# STM32L485JEY6 register map
File version: 1.0
Registers are 32-bit, access not given, reset 0x0 unless marked. A register's access mark holds for its fields unless they carry their own. Offsets are from the block's base; [hi:lo] are bit positions; {n}, {i} and the like mark numbered series.

## DAC
Base 0x40007400
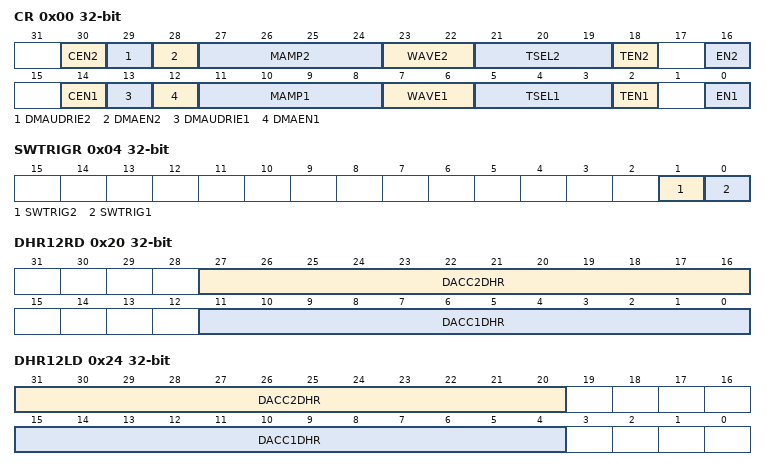
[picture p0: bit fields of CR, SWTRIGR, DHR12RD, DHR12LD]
0x00 CR
  [30] CEN2, [29] DMAUDRIE2, [28] DMAEN2, [27:24] MAMP2, [23:22] WAVE2, [21:19] TSEL2, [18] TEN2, [16] EN2, [14] CEN1, [13] DMAUDRIE1, [12] DMAEN1, [11:8] MAMP1, [7:6] WAVE1, [5:3] TSEL1, [2] TEN1, [0] EN1
0x04 SWTRIGR
  [1] SWTRIG2, [0] SWTRIG1
0x08 DHR12R1
  [11:0] DACC1DHR
0x0C DHR12L1
  [15:4] DACC1DHR
0x10 DHR8R1
  [7:0] DACC1DHR
0x14 DHR12R2
  [11:0] DACC2DHR
0x18 DHR12L2
  [15:4] DACC2DHR
0x1C DHR8R2
  [7:0] DACC2DHR
0x20 DHR12RD
  [27:16] DACC2DHR, [11:0] DACC1DHR
0x24 DHR12LD
  [31:20] DACC2DHR, [15:4] DACC1DHR
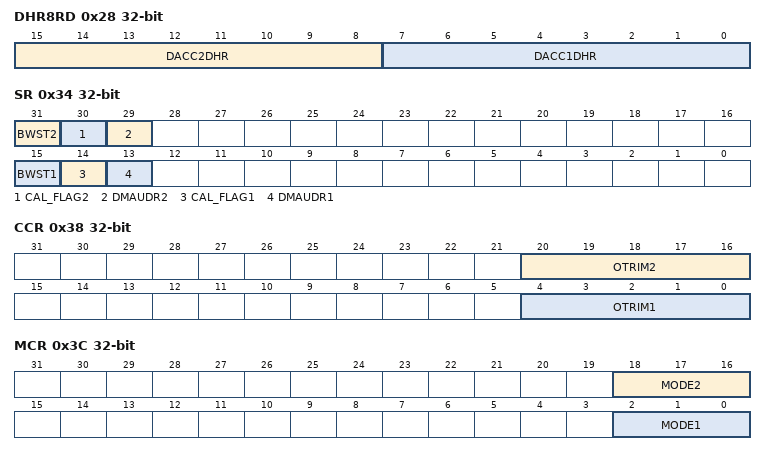
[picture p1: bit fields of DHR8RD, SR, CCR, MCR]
0x28 DHR8RD
  [15:8] DACC2DHR, [7:0] DACC1DHR
0x2C DOR1
  [11:0] DACC1DOR
0x30 DOR2
  [11:0] DACC2DOR
0x34 SR
  [31] BWST2, [30] CAL_FLAG2, [29] DMAUDR2, [15] BWST1, [14] CAL_FLAG1, [13] DMAUDR1
0x38 CCR
  [20:16] OTRIM2, [4:0] OTRIM1
0x3C MCR
  [18:16] MODE2, [2:0] MODE1
0x40 SHSR1
  [9:0] TSAMPLE1
0x44 SHSR2
  [9:0] TSAMPLE2
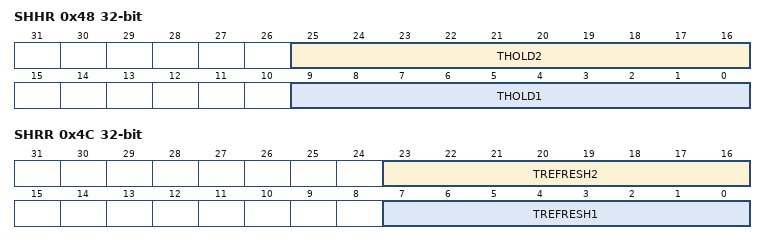
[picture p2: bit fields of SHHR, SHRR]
0x48 SHHR
  [25:16] THOLD2, [9:0] THOLD1
0x4C SHRR
  [23:16] TREFRESH2, [7:0] TREFRESH1

## DAC1
Base 0x40007400
Registers as DAC; these are added or differ:
0x08 DHR12R1
  [11:0] DACC1DHR
0x0C DHR12L1
  [15:4] DACC1DHR
0x10 DHR8R1
  [7:0] DACC1DHR
0x14 DHR12R2
  [11:0] DACC2DHR
0x18 DHR12L2
  [15:4] DACC2DHR
0x1C DHR8R2
  [7:0] DACC2DHR
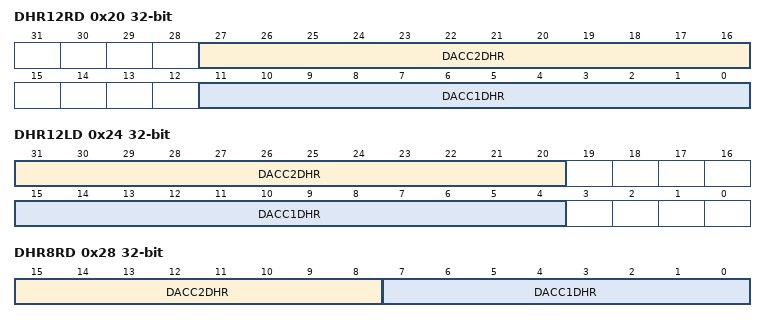
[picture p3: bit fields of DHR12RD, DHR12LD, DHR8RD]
0x20 DHR12RD
  [27:16] DACC2DHR, [11:0] DACC1DHR
0x24 DHR12LD
  [31:20] DACC2DHR, [15:4] DACC1DHR
0x28 DHR8RD
  [15:8] DACC2DHR, [7:0] DACC1DHR
0x2C DOR1
  [11:0] DACC1DOR
0x30 DOR2
  [11:0] DACC2DOR

## OPAMP
Base 0x40007800
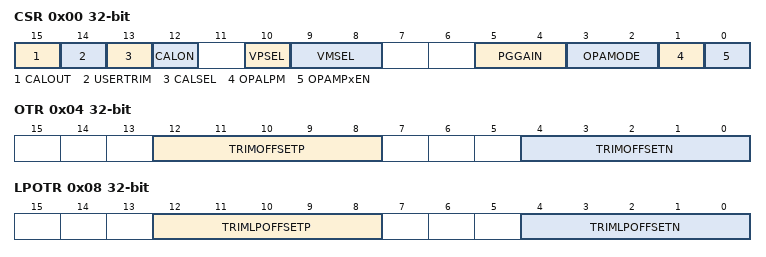
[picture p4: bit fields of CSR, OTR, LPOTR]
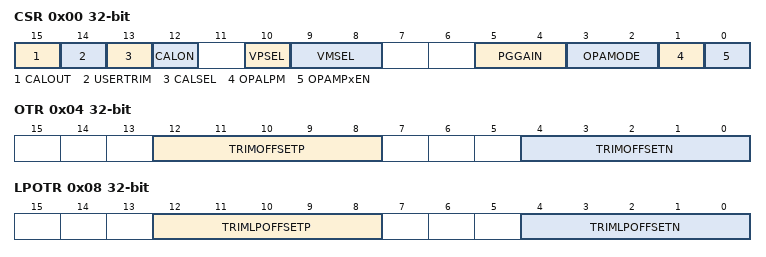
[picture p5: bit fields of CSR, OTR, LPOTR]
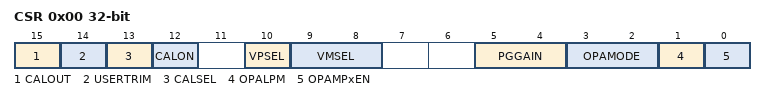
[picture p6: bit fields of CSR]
0x00 CSR
  [15] CALOUT, [14] USERTRIM, [13] CALSEL, [12] CALON, [10] VPSEL, [9:8] VMSEL, [5:4] PGGAIN, [3:2] OPAMODE, [1] OPALPM, [0] OPAMPxEN
0x04 OTR
  [12:8] TRIMOFFSETP, [4:0] TRIMOFFSETN
0x08 LPOTR
  [12:8] TRIMLPOFFSETP, [4:0] TRIMLPOFFSETN

## OPAMP1
Base 0x40007800
Same registers: OPAMP2 0x40007810
0x00 CSR
  [15] CALOUT, [14] USERTRIM, [13] CALSEL, [12] CALON, [10] VPSEL, [9:8] VMSEL, [5:4] PGGAIN, [3:2] OPAMODE, [1] OPALPM, [0] OPAMPxEN
0x04 OTR
  [12:8] TRIMOFFSETP, [4:0] TRIMOFFSETN
0x08 LPOTR
  [12:8] TRIMLPOFFSETP, [4:0] TRIMLPOFFSETN

## OPAMP12_COMMON
Base 0x40007800
0x00 CSR
  [15] CALOUT, [14] USERTRIM, [13] CALSEL, [12] CALON, [10] VPSEL, [9:8] VMSEL, [5:4] PGGAIN, [3:2] OPAMODE, [1] OPALPM, [0] OPAMPxEN

## LPTIM1
Base 0x40007C00
Same registers: LPTIM2 0x40009400
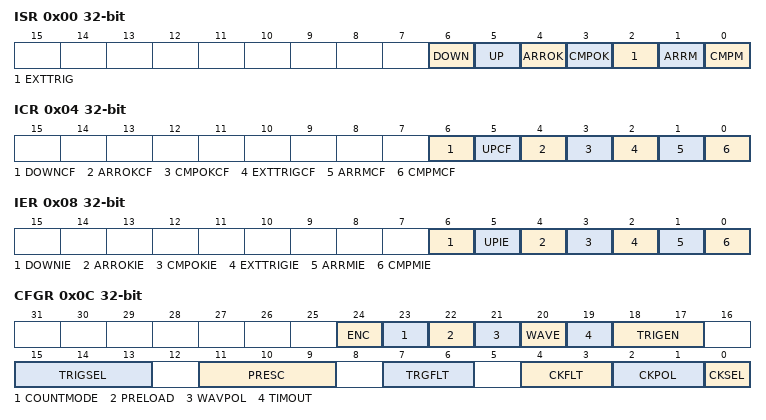
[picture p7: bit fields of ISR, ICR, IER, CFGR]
0x00 ISR
  [6] DOWN, [5] UP, [4] ARROK, [3] CMPOK, [2] EXTTRIG, [1] ARRM, [0] CMPM
0x04 ICR
  [6] DOWNCF, [5] UPCF, [4] ARROKCF, [3] CMPOKCF, [2] EXTTRIGCF, [1] ARRMCF, [0] CMPMCF
0x08 IER
  [6] DOWNIE, [5] UPIE, [4] ARROKIE, [3] CMPOKIE, [2] EXTTRIGIE, [1] ARRMIE, [0] CMPMIE
0x0C CFGR
  [24] ENC, [23] COUNTMODE, [22] PRELOAD, [21] WAVPOL, [20] WAVE, [19] TIMOUT, [18:17] TRIGEN, [15:13] TRIGSEL, [11:9] PRESC, [7:6] TRGFLT, [4:3] CKFLT, [2:1] CKPOL, [0] CKSEL
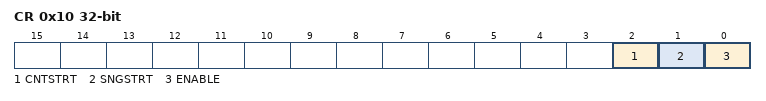
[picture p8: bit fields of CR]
0x10 CR
  [2] CNTSTRT, [1] SNGSTRT, [0] ENABLE
0x14 CMP
  [15:0] CMP
0x18 ARR
  [15:0] ARR
0x1C CNT
  [15:0] CNT
0x20 OR
  [1:0] OR

## SWPMI1
Base 0x40008800
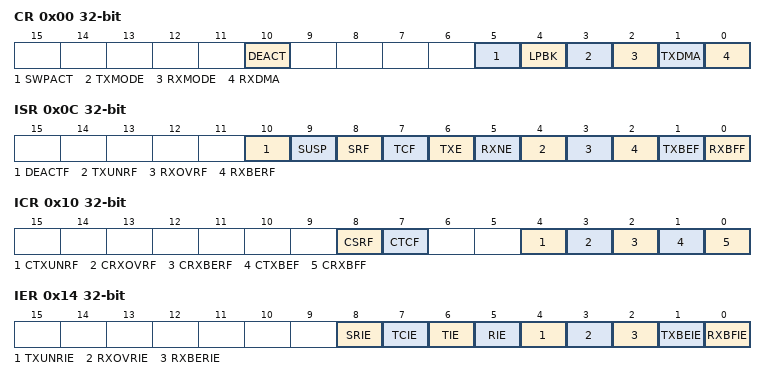
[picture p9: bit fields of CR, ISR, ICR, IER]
0x00 CR
  [10] DEACT, [5] SWPACT, [4] LPBK, [3] TXMODE, [2] RXMODE, [1] TXDMA, [0] RXDMA
0x04 BRR
  [5:0] BR
0x0C ISR
  [10] DEACTF, [9] SUSP, [8] SRF, [7] TCF, [6] TXE, [5] RXNE, [4] TXUNRF, [3] RXOVRF, [2] RXBERF, [1] TXBEF, [0] RXBFF
0x10 ICR
  [8] CSRF, [7] CTCF, [4] CTXUNRF, [3] CRXOVRF, [2] CRXBERF, [1] CTXBEF, [0] CRXBFF
0x14 IER
  [8] SRIE, [7] TCIE, [6] TIE, [5] RIE, [4] TXUNRIE, [3] RXOVRIE, [2] RXBERIE, [1] TXBEIE, [0] RXBFIE
0x18 RFL
  [1:0] RFL_0_1
0x1C TDR
  [31:0] TD
0x20 RDR
  [31:0] RD
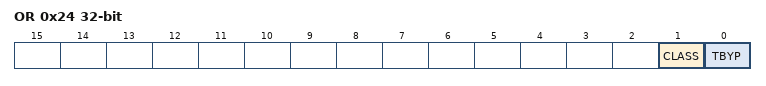
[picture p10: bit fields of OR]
0x24 OR
  [1] CLASS, [0] TBYP

## SYSCFG
Base 0x40010000
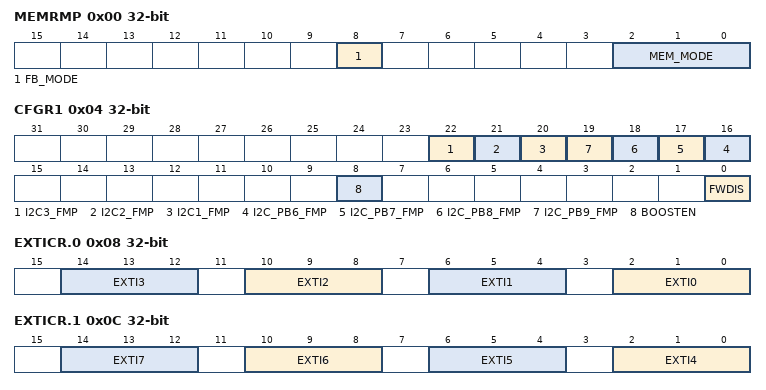
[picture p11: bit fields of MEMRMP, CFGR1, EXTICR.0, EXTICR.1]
0x00 MEMRMP
  [8] FB_MODE, [2:0] MEM_MODE
0x04 CFGR1
  [22] I2C3_FMP, [21] I2C2_FMP, [20] I2C1_FMP, [n+10] I2C_PB{n}_FMP (n=6..9), [8] BOOSTEN, [0] FWDIS
0x08 EXTICR.0
  [4n+2:4n] EXTI{n} (n=0..3)
0x0C EXTICR.1
  [4n-14:4n-16] EXTI{n} (n=4..7)
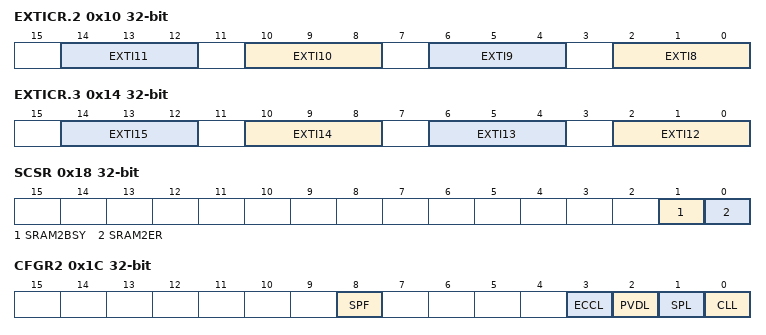
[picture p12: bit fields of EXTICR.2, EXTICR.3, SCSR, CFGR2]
0x10 EXTICR.2
  [4n-30:4n-32] EXTI{n} (n=8..11)
0x14 EXTICR.3
  [4n-46:4n-48] EXTI{n} (n=12..15)
0x18 SCSR
  [1] SRAM2BSY, [0] SRAM2ER
0x1C CFGR2
  [8] SPF, [3] ECCL, [2] PVDL, [1] SPL, [0] CLL
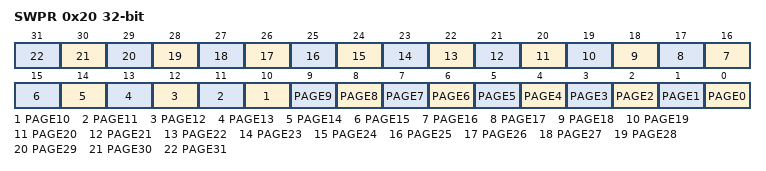
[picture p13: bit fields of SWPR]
0x20 SWPR
  [n] PAGE{n} (n=0..31)
0x24 SKR
  [7:0] KEY
